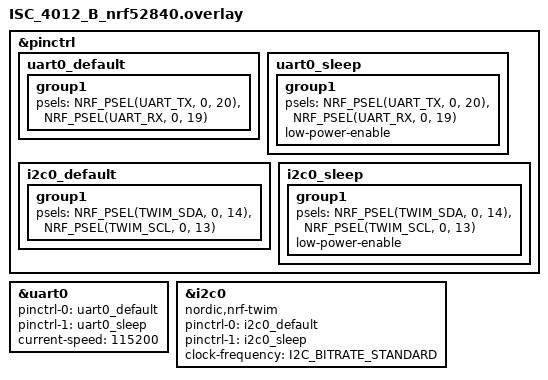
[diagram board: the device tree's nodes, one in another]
&pinctrl {
    uart0_default: uart0_default {
        group1 {
            psels = <NRF_PSEL(UART_TX, 0, 20)>,
                    <NRF_PSEL(UART_RX, 0, 19)>;
        };
    };

    uart0_sleep: uart0_sleep {
        group1 {
            psels = <NRF_PSEL(UART_TX, 0, 20)>,
                    <NRF_PSEL(UART_RX, 0, 19)>;
            low-power-enable;
        };
    };

    i2c0_default: i2c0_default {
        group1 {
            psels = <NRF_PSEL(TWIM_SDA, 0, 14)>,
                    <NRF_PSEL(TWIM_SCL, 0, 13)>;
        };
    };

    i2c0_sleep: i2c0_sleep {
        group1 {
            psels = <NRF_PSEL(TWIM_SDA, 0, 14)>,
                    <NRF_PSEL(TWIM_SCL, 0, 13)>;
            low-power-enable;
        };
    };
};

&uart0 {
    status = "okay";
    pinctrl-0 = <&uart0_default>;
    pinctrl-1 = <&uart0_sleep>;
    pinctrl-names = "default", "sleep";
    current-speed = <115200>;
};

&i2c0 {
    compatible = "nordic,nrf-twim";
    status = "okay";
    pinctrl-0 = <&i2c0_default>;
    pinctrl-1 = <&i2c0_sleep>;
    pinctrl-names = "default", "sleep";
    clock-frequency = <I2C_BITRATE_STANDARD>;
};
